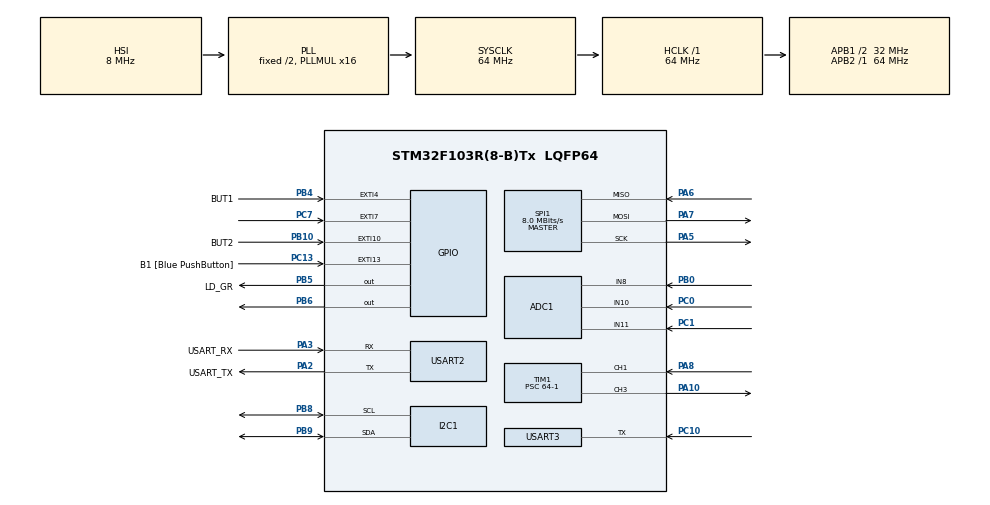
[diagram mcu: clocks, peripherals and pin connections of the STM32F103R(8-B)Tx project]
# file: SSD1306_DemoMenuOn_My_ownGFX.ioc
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Mcu.Family=STM32F1
NVIC.ADC1_2_IRQn=true\:0\:0\:false\:false\:true\:true\:true
PA2.GPIO_PuPd=GPIO_NOPULL
PA6.Mode=Full_Duplex_Master
NVIC.I2C1_EV_IRQn=true\:13\:0\:true\:false\:true\:true\:true
SPI1.VirtualType=VM_MASTER
ADC1.ContinuousConvMode=ENABLE
PB4.GPIO_ModeDefaultEXTI=GPIO_MODE_IT_FALLING
Dma.I2C1_TX.1.Mode=DMA_NORMAL
PC10.Signal=USART3_TX
PA14.GPIO_Label=TCK
PA3.GPIO_PuPd=GPIO_NOPULL
PA2.GPIO_Speed=GPIO_SPEED_FREQ_LOW
NVIC.TIM1_UP_IRQn=true\:5\:0\:true\:false\:true\:true\:true
PA3.GPIO_Speed=GPIO_SPEED_FREQ_LOW
ADC1.Channel-8\#ChannelRegularConversion=ADC_CHANNEL_10
RCC.SYSCLKSource=RCC_SYSCLKSOURCE_PLLCLK
ProjectManager.StackSize=0x400
PD1-OSC_OUT.Signal=RCC_OSC_OUT
Dma.I2C1_TX.1.Direction=DMA_MEMORY_TO_PERIPH
TIM1.Prescaler=64-1
ADC1.Channel-5\#ChannelRegularConversion=ADC_CHANNEL_8
SPI1.Direction=SPI_DIRECTION_2LINES
RCC.HCLKFreq_Value=64000000
RCC.APB2TimFreq_Value=64000000
TIM3.Period=726-1
PB6.Signal=GPIO_Output
PC7.Signal=GPXTI7
Dma.I2C1_RX.0.PeriphDataAlignment=DMA_PDATAALIGN_BYTE
Dma.I2C1_TX.1.PeriphInc=DMA_PINC_DISABLE
SPI1.CalculateBaudRate=8.0 MBits/s
RCC.AHBFreq_Value=64000000
Dma.I2C1_RX.0.Priority=DMA_PRIORITY_LOW
NVIC.EXTI15_10_IRQn=true\:7\:0\:true\:false\:true\:true\:true
Dma.I2C1_RX.0.Mode=DMA_NORMAL
RCC.RTCClockSelection=RCC_RTCCLKSOURCE_LSE
RCC.PLLMUL=RCC_PLL_MUL16
Dma.ADC1.2.MemDataAlignment=DMA_MDATAALIGN_WORD
PC14-OSC32_IN.Mode=LSE-External-Oscillator
PA14.Mode=Serial_Wire
TIM3.Prescaler=2-1
NVIC.TIM2_IRQn=true\:0\:0\:false\:false\:true\:true\:true
SH.ADCx_IN8.0=ADC1_IN8,IN8
Dma.ADC1.2.Direction=DMA_PERIPH_TO_MEMORY
PA8.Signal=S_TIM1_CH1
Dma.I2C1_RX.0.Direction=DMA_PERIPH_TO_MEMORY
NVIC.I2C1_ER_IRQn=true\:13\:0\:true\:false\:true\:true\:true
TIM1.Channel-Input_Capture2_from_TI1=TIM_CHANNEL_2
VP_TIM1_VS_ClockSourceINT.Mode=Internal
PC7.GPIO_ModeDefaultEXTI=GPIO_MODE_IT_FALLING
Mcu.Package=LQFP64
PB9.Signal=I2C1_SDA
TIM2.Prescaler=64-1
PA6.Signal=SPI1_MISO
ADC1.EnableInjectedConversion=DISABLE
USART2.VirtualMode=VM_ASYNC
PC13-TAMPER-RTC.GPIO_PuPd=GPIO_NOPULL
PA2.GPIO_Label=USART_TX
PA10.Signal=S_TIM1_CH3
PB5.GPIO_Label=LD_GR
Dma.Request2=ADC1
TIM1.ICPolarity_CH2=TIM_INPUTCHANNELPOLARITY_FALLING
Dma.Request1=I2C1_TX
RCC.APB1TimFreq_Value=64000000
Dma.Request0=I2C1_RX
SPI1.BaudRatePrescaler=SPI_BAUDRATEPRESCALER_8
ADC1.SamplingTime-8\#ChannelRegularConversion=ADC_SAMPLETIME_13CYCLES_5
VP_TIM3_VS_ClockSourceINT.Mode=Internal
PB4.Signal=GPXTI4
Dma.ADC1.2.Mode=DMA_CIRCULAR
PA3.Signal=USART2_RX
PA5.Mode=Full_Duplex_Master
PA2.GPIO_Mode=GPIO_MODE_AF_PP
Dma.I2C1_TX.1.PeriphDataAlignment=DMA_PDATAALIGN_BYTE
PB5.GPIO_ModeDefaultOutputPP=GPIO_MODE_OUTPUT_OD
PC15-OSC32_OUT.Mode=LSE-External-Oscillator
NVIC.DMA1_Channel6_IRQn=true\:0\:0\:false\:false\:true\:false\:true
Dma.I2C1_RX.0.PeriphInc=DMA_PINC_DISABLE
NVIC.EXTI4_IRQn=true\:7\:0\:true\:false\:true\:true\:true
Dma.I2C1_RX.0.MemDataAlignment=DMA_MDATAALIGN_BYTE
PA7.Mode=Full_Duplex_Master
PD1-OSC_OUT.Mode=HSE-External-Clock-Source
ADC1.Rank-8\#ChannelRegularConversion=2
Dma.ADC1.2.PeriphDataAlignment=DMA_PDATAALIGN_HALFWORD
PC10.Mode=Half_duplex(single_wire_mode)
PC13-TAMPER-RTC.Signal=GPXTI13
PD0-OSC_IN.Signal=RCC_OSC_IN
PC0.Signal=ADCx_IN10
RCC.APB1CLKDivider=RCC_HCLK_DIV2
PC14-OSC32_IN.Signal=RCC_OSC32_IN
RCC.ADCPresc=RCC_ADCPCLK2_DIV8
PA3.Mode=Asynchronous
PA13.Signal=SYS_JTMS-SWDIO
TIM1.Pulse-PWM\ Generation3\ CH3=11
Dma.ADC1.2.MemInc=DMA_MINC_ENABLE
SH.S_TIM1_CH1.0=TIM1_CH1,Input_Capture1_from_TI1
SH.S_TIM1_CH1.1=TIM1_CH1,Input_Capture2_from_TI1
ProjectManager.TargetToolchain=STM32CubeIDE
PB10.GPIO_Label=BUT2
I2C1.I2C_Mode=I2C_Fast
PA3.GPIO_Mode=GPIO_MODE_AF_PP
PB9.Mode=I2C
Dma.I2C1_RX.0.MemInc=DMA_MINC_ENABLE
Dma.I2C1_TX.1.Instance=DMA1_Channel6
RCC.USBFreq_Value=64000000
PC15-OSC32_OUT.Signal=RCC_OSC32_OUT
PB10.Signal=GPXTI10
PD0-OSC_IN.Mode=HSE-External-Clock-Source
PA5.Signal=SPI1_SCK
NVIC.TIM1_TRG_COM_IRQn=true\:5\:0\:true\:false\:true\:true\:true
board=NUCLEO-F103RB
Dma.I2C1_TX.1.Priority=DMA_PRIORITY_LOW
PC13-TAMPER-RTC.GPIO_Label=B1 [Blue PushButton]
RCC.APB2Freq_Value=64000000
SH.ADCx_IN11.0=ADC1_IN11,IN11
PB4.GPIO_Label=BUT1
VP_TIM2_VS_ClockSourceINT.Mode=Internal
SPI1.Mode=SPI_MODE_MASTER
Dma.I2C1_TX.1.MemInc=DMA_MINC_ENABLE
Dma.I2C1_TX.1.MemDataAlignment=DMA_MDATAALIGN_BYTE
TIM2.Period=100
ADC1.Rank-9\#ChannelRegularConversion=3
ADC1.NbrOfConversion=3
PA13.Mode=Serial_Wire
PB10.GPIO_ModeDefaultEXTI=GPIO_MODE_IT_FALLING
Mcu.Name=STM32F103R(8-B)Tx
PA2.Signal=USART2_TX
PA13.GPIO_Label=TMS
Dma.ADC1.2.Instance=DMA1_Channel1
ADC1.ExternalTrigConv=ADC_EXTERNALTRIGCONV_T3_TRGO
ADC1.Channel-9\#ChannelRegularConversion=ADC_CHANNEL_11
NVIC.TIM1_CC_IRQn=true\:5\:0\:true\:false\:true\:true\:true
RCC.SYSCLKFreq_VALUE=64000000
Dma.ADC1.2.Priority=DMA_PRIORITY_LOW
PB5.Signal=GPIO_Output
USART3.Mode=MODE_RX
ADC1.master=1
Dma.ADC1.2.PeriphInc=DMA_PINC_DISABLE
USART3.VirtualMode=VM_ASYNC
TIM1.Channel-Input_Capture1_from_TI1=TIM_CHANNEL_1
PB5.GPIO_PuPd=GPIO_PULLUP
NVIC.EXTI9_5_IRQn=true\:14\:0\:true\:false\:true\:true\:true
PA14.Signal=SYS_JTCK-SWCLK
SH.ADCx_IN10.0=ADC1_IN10,IN10
NVIC.TIM1_BRK_IRQn=true\:5\:0\:true\:false\:true\:true\:true
ProjectManager.HeapSize=0x200
SH.S_TIM1_CH3.0=TIM1_CH3,PWM Generation3 CH3
ADC1.SamplingTime-5\#ChannelRegularConversion=ADC_SAMPLETIME_13CYCLES_5
NVIC.PriorityGroup=NVIC_PRIORITYGROUP_4
ADC1.NbrOfConversionFlag=1
PB8.Mode=I2C
ADC1.EnableRegularConversion=ENABLE
PA2.Mode=Asynchronous
PB8.Signal=I2C1_SCL
NVIC.DMA1_Channel7_IRQn=true\:0\:0\:false\:false\:true\:false\:true
ADC1.SamplingTime-9\#ChannelRegularConversion=ADC_SAMPLETIME_13CYCLES_5
NVIC.DMA1_Channel1_IRQn=true\:0\:0\:false\:false\:true\:false\:true
TIM1.Channel-PWM\ Generation3\ CH3=TIM_CHANNEL_3
TIM3.TIM_MasterOutputTrigger=TIM_TRGO_UPDATE
RCC.APB1Freq_Value=32000000
PB0.Signal=ADCx_IN8
Dma.I2C1_RX.0.Instance=DMA1_Channel7
ADC1.Rank-5\#ChannelRegularConversion=1
PC1.Signal=ADCx_IN11
PA3.GPIO_Label=USART_RX
PA7.Signal=SPI1_MOSI

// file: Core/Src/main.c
/* USER CODE BEGIN Header */
/**
  ******************************************************************************
  * @file           : main.c
  * @brief          : Main program body
  ******************************************************************************
  * @attention
  *
  * <h2><center>&copy; Copyright (c) 2021 STMicroelectronics.
  * All rights reserved.</center></h2>
  *
  * This software component is licensed by ST under BSD 3-Clause license,
  * the "License"; You may not use this file except in compliance with the
  * License. You may obtain a copy of the License at:
  *                        opensource.org/licenses/BSD-3-Clause
  *
  ******************************************************************************
  */
/* USER CODE END Header */
#include "main.h"
#include "adc.h"
#include "dma.h"
#include "i2c.h"
#include "spi.h"
#include "tim.h"
#include "usart.h"
#include "gpio.h"

/* USER CODE BEGIN Includes */
#include "OLED_SSD1306_Task.h"

/* USER CODE END Includes */

void SystemClock_Config(void);

/* USER CODE BEGIN 0 */
void HAL_GPIO_EXTI_Callback(uint16_t GPIO_Pin)
{
	OLED_EXTI_CallBack(GPIO_Pin);
}

void HAL_TIM_IC_CaptureCallback(TIM_HandleTypeDef *htim)
{
	HCSR04_TIM_IC_CaptureCallback(htim);
}
void HAL_TIM_PeriodElapsedCallback(TIM_HandleTypeDef *htim)
{
	if(htim->Instance==TIM2)
	{
		RC5_100usTimer();
	}

}
void HAL_ADC_ConvCpltCallback(ADC_HandleTypeDef* hadc)
{
	if(hadc->Instance == ADC1)
	{
		ADC_MicrophoneConvCpltCallBack();
	}
}

/* USER CODE END 0 */

int main(void)
{

  /* MCU Configuration--------------------------------------------------------*/

  /* Reset of all peripherals, Initializes the Flash interface and the Systick. */
  HAL_Init();

  /* Configure the system clock */
  SystemClock_Config();

  /* Initialize all configured peripherals */
  MX_GPIO_Init();
  MX_DMA_Init();
  MX_USART2_UART_Init();
  MX_I2C1_Init();
  MX_USART3_UART_Init();
  MX_TIM1_Init();
  MX_TIM2_Init();
  MX_ADC1_Init();
  MX_SPI1_Init();
  MX_TIM3_Init();
  /* USER CODE BEGIN 2 */
  OLED_Init();
  MFRC522_Init();
  /* USER CODE END 2 */

  /* Infinite loop */
  /* USER CODE BEGIN WHILE */
  while (1)
  {
	  OLED_Task();

	//  HAL_GPIO_TogglePin(LD_GR_GPIO_Port, LD_GR_Pin);
    /* USER CODE END WHILE */

  }
}

void SystemClock_Config(void)
{
  RCC_OscInitTypeDef RCC_OscInitStruct = {0};
  RCC_ClkInitTypeDef RCC_ClkInitStruct = {0};
  RCC_PeriphCLKInitTypeDef PeriphClkInit = {0};

  /** Initializes the RCC Oscillators according to the specified parameters
  * in the RCC_OscInitTypeDef structure.
  */
  RCC_OscInitStruct.OscillatorType = RCC_OSCILLATORTYPE_HSI;
  RCC_OscInitStruct.HSIState = RCC_HSI_ON;
  RCC_OscInitStruct.HSICalibrationValue = RCC_HSICALIBRATION_DEFAULT;
  RCC_OscInitStruct.PLL.PLLState = RCC_PLL_ON;
  RCC_OscInitStruct.PLL.PLLSource = RCC_PLLSOURCE_HSI_DIV2;
  RCC_OscInitStruct.PLL.PLLMUL = RCC_PLL_MUL16;
  if (HAL_RCC_OscConfig(&RCC_OscInitStruct) != HAL_OK)
  {
    Error_Handler();
  }
  /** Initializes the CPU, AHB and APB buses clocks
  */
  RCC_ClkInitStruct.ClockType = RCC_CLOCKTYPE_HCLK|RCC_CLOCKTYPE_SYSCLK
                              |RCC_CLOCKTYPE_PCLK1|RCC_CLOCKTYPE_PCLK2;
  RCC_ClkInitStruct.SYSCLKSource = RCC_SYSCLKSOURCE_PLLCLK;
  RCC_ClkInitStruct.AHBCLKDivider = RCC_SYSCLK_DIV1;
  RCC_ClkInitStruct.APB1CLKDivider = RCC_HCLK_DIV2;
  RCC_ClkInitStruct.APB2CLKDivider = RCC_HCLK_DIV1;

  if (HAL_RCC_ClockConfig(&RCC_ClkInitStruct, FLASH_LATENCY_2) != HAL_OK)
  {
    Error_Handler();
  }
  PeriphClkInit.PeriphClockSelection = RCC_PERIPHCLK_ADC;
  PeriphClkInit.AdcClockSelection = RCC_ADCPCLK2_DIV8;
  if (HAL_RCCEx_PeriphCLKConfig(&PeriphClkInit) != HAL_OK)
  {
    Error_Handler();
  }
}

void Error_Handler(void)
{
  __disable_irq();
  while (1)
  {
  }
}

/************************ (C) COPYRIGHT STMicroelectronics *****END OF FILE****/
